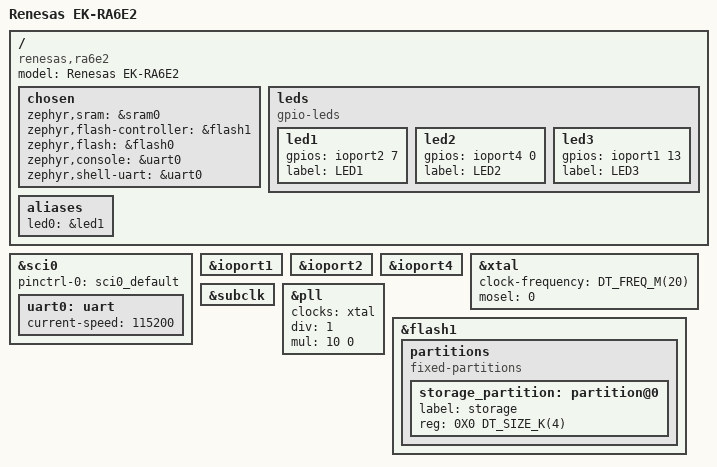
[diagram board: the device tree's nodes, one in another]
/*
 * Copyright (c) 2024 Renesas Electronics Corporation
 * SPDX-License-Identifier: Apache-2.0
 */

/dts-v1/;

#include <renesas/ra/ra6/r7fa6e2bb3cfm.dtsi>
#include <dt-bindings/gpio/gpio.h>

#include "ek_ra6e2-pinctrl.dtsi"

/ {
	model = "Renesas EK-RA6E2";
	compatible = "renesas,ra6e2", "renesas,ra";

	chosen {
		zephyr,sram = &sram0;
		zephyr,flash-controller = &flash1;
		zephyr,flash = &flash0;
		zephyr,console = &uart0;
		zephyr,shell-uart = &uart0;
	};

	leds {
		compatible = "gpio-leds";
		led1: led1 {
			gpios = <&ioport2 7 GPIO_ACTIVE_HIGH>;
			label = "LED1";
		};
		led2: led2 {
			gpios = <&ioport4 0 GPIO_ACTIVE_HIGH>;
			label = "LED2";
		};
		led3: led3 {
			gpios = <&ioport1 13 GPIO_ACTIVE_HIGH>;
			label = "LED3";
		};
	};

	aliases {
		led0 = &led1;
	};
};

&sci0 {
	pinctrl-0 = <&sci0_default>;
	pinctrl-names = "default";
	status = "okay";
	uart0: uart {
		current-speed = <115200>;
		status = "okay";
	};
};

&ioport1 {
	status = "okay";
};

&ioport2 {
	status = "okay";
};

&ioport4 {
	status = "okay";
};

&xtal {
	clock-frequency = <DT_FREQ_M(20)>;
	mosel = <0>;
	#clock-cells = <0>;
	status = "okay";
};

&subclk {
	status = "okay";
};

&pll {
	clocks = <&xtal>;
	div = <1>;
	mul = <10 0>;
	status = "okay";
};

&flash1 {
	partitions {
		compatible = "fixed-partitions";
		#address-cells = <1>;
		#size-cells = <1>;

		storage_partition: partition@0 {
			label = "storage";
			reg = <0X0 DT_SIZE_K(4)>;
		};
	};
};
